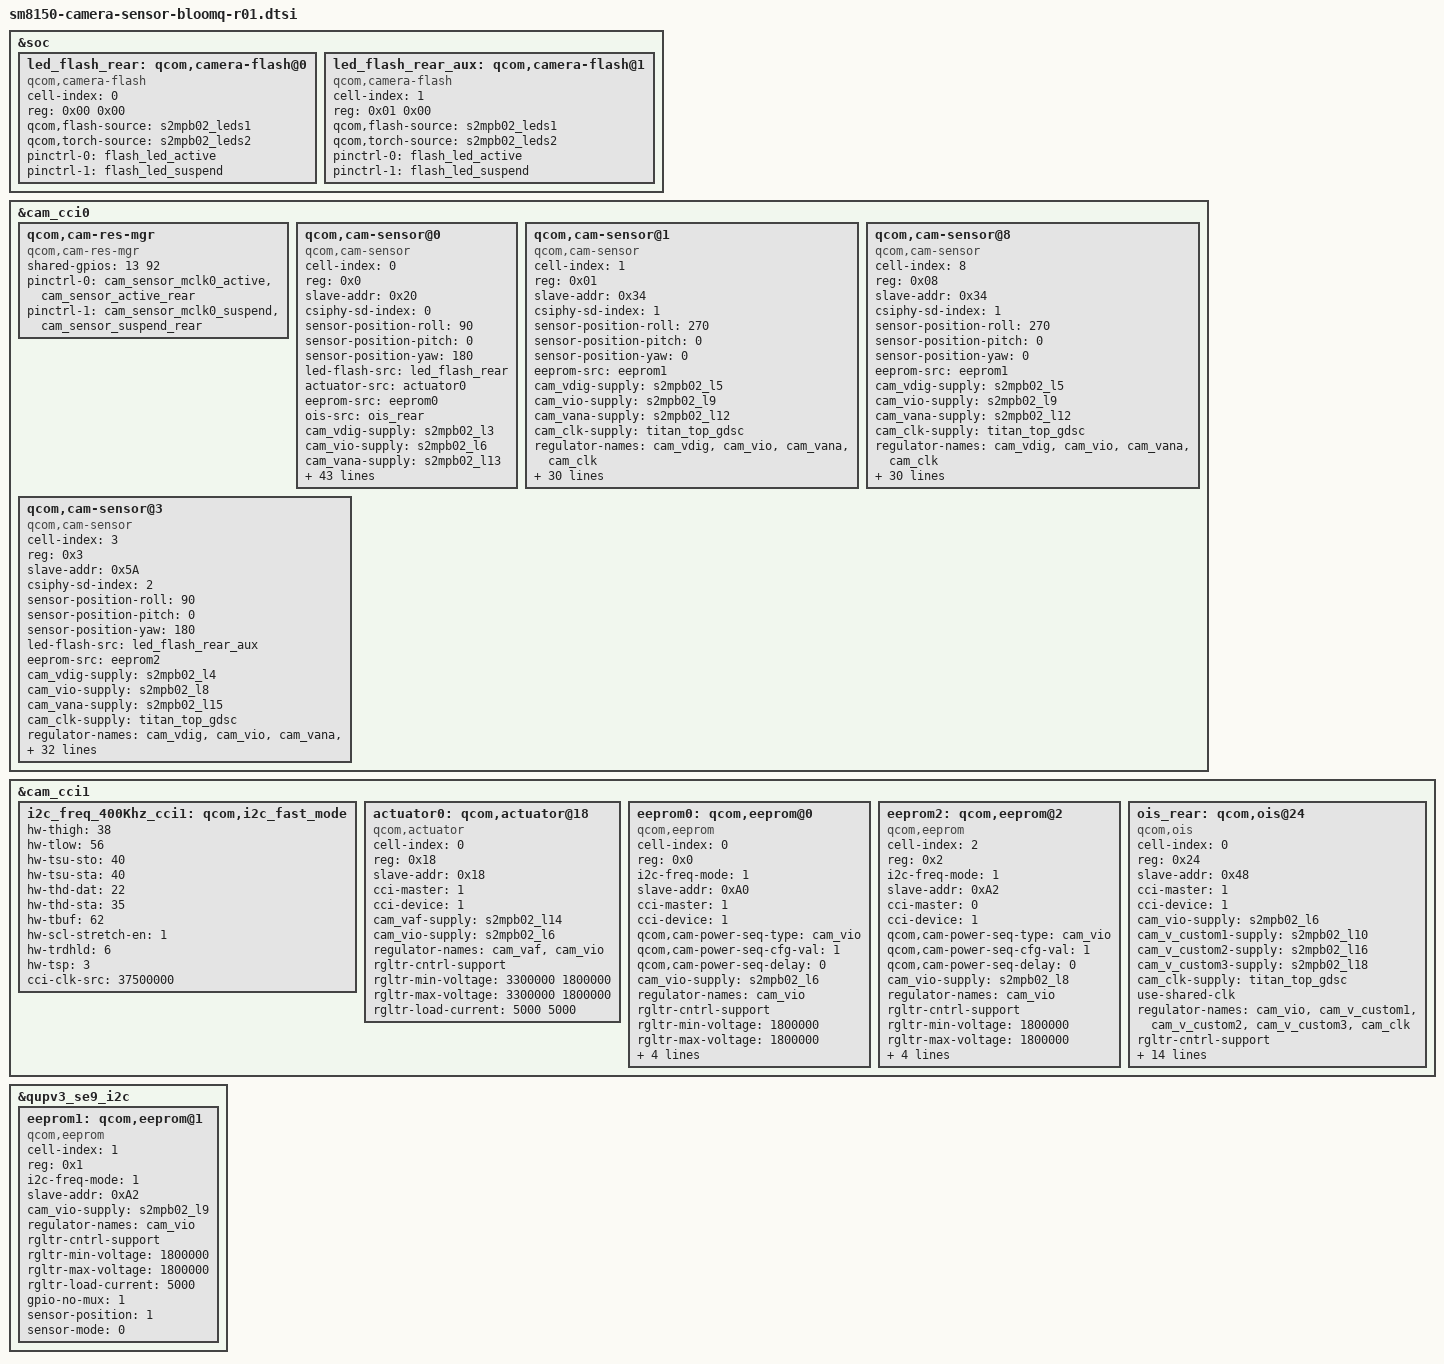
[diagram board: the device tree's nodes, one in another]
/*
 * Copyright (c) 2018, The Linux Foundation. All rights reserved.
 *
 * This program is free software; you can redistribute it and/or modify
 * it under the terms of the GNU General Public License version 2 and
 * only version 2 as published by the Free Software Foundation.
 *
 * This program is distributed in the hope that it will be useful,
 * but WITHOUT ANY WARRANTY; without even the implied warranty of
 * MERCHANTABILITY or FITNESS FOR A PARTICULAR PURPOSE.  See the
 * GNU General Public License for more details.
 */

&soc{
	led_flash_rear: qcom,camera-flash@0 {
		cell-index = <0>;
		reg = <0x00 0x00>;
		compatible = "qcom,camera-flash";
		qcom,flash-source = <&s2mpb02_leds1>;
		qcom,torch-source = <&s2mpb02_leds2>;
		pinctrl-names = "cam_default", "cam_suspend";
		pinctrl-0 = <&flash_led_active>;
		pinctrl-1 = <&flash_led_suspend>;
		status = "ok";
	};

	led_flash_rear_aux: qcom,camera-flash@1 {
		cell-index = <1>;
		reg = <0x01 0x00>;
		compatible = "qcom,camera-flash";
		qcom,flash-source = <&s2mpb02_leds1>;
		qcom,torch-source = <&s2mpb02_leds2>;
		pinctrl-names = "cam_default", "cam_suspend";
		pinctrl-0 = <&flash_led_active>;
		pinctrl-1 = <&flash_led_suspend>;
		status = "ok";
	};
};


&cam_cci0 {
	/*qcom,cam-res-mgr {
		compatible = "qcom,cam-res-mgr";
		shared-gpios = <13 15>;
		pinctrl-names = "cam_res_mgr_default", "cam_res_mgr_suspend";
		status = "ok";
		pinctrl-0 = <&cam_sensor_mclk0_active
		    &cam_sensor_mclk2_active>;
		pinctrl-1 = <&cam_sensor_mclk0_suspend
    		&cam_sensor_mclk2_suspend>;
	};*/
	qcom,cam-res-mgr {
		compatible = "qcom,cam-res-mgr";
		shared-gpios = <13 92>;
		pinctrl-names = "cam_res_mgr_default", "cam_res_mgr_suspend";
		status = "ok";
		pinctrl-0 = <&cam_sensor_mclk0_active &cam_sensor_active_rear>;
		pinctrl-1 = <&cam_sensor_mclk0_suspend &cam_sensor_suspend_rear>;
	};

	qcom,cam-sensor@0 {
                cell-index = <0>; /*REAR MAIN*/
                compatible = "qcom,cam-sensor";
                reg = <0x0>;
                slave-addr = <0x20>;
                csiphy-sd-index = <0>;
                sensor-position-roll = <90>;
                sensor-position-pitch = <0>;
                sensor-position-yaw = <180>;
                led-flash-src = <&led_flash_rear>;
                actuator-src = <&actuator0>;
                eeprom-src = <&eeprom0>;
                ois-src = <&ois_rear>;
                cam_vdig-supply = <&s2mpb02_l3>;        //VDD_MAINCAM_1P05
                cam_vio-supply = <&s2mpb02_l6>;         //VDD_MAINCAM_IO_1P8
                cam_vana-supply = <&s2mpb02_l13>;       //VDD_MAINCAM_A2P4
                cam_vaf-supply = <&s2mpb02_l14>;        //VDD_MAINCAM_AF_3P3
                cam_v_custom1-supply = <&s2mpb02_l2>;   //VDD_MAINCAM_RET_1P05
                cam_v_custom2-supply = <&s2mpb02_l1>;   //VDD_MAINCAM_DRAM_1P1
                cam_v_custom3-supply = <&s2mpb02_l10>;  //VDD_OIS_1P8
                cam_v_custom4-supply = <&s2mpb02_l16>;  //VDD_OIS_2P8
                cam_v_custom5-supply = <&s2mpb02_l18>;  //VDD_OIS_VM_2P8
                cam_v_custom6-supply = <&s2mpb02_l17>;  //VDD_MAINCAM_A2P8
                cam_clk-supply = <&titan_top_gdsc>;
                regulator-names = "cam_vdig", "cam_vio", "cam_vana", "cam_vaf", "cam_v_custom1", "cam_v_custom2", "cam_v_custom3", "cam_v_custom4", "cam_v_custom5", "cam_v_custom6", "cam_clk";
                rgltr-cntrl-support;
                rgltr-min-voltage = <1050000 1800000 2400000 3300000 700000  1100000 1800000 2800000 2800000 2800000 0>;
                rgltr-max-voltage = <1050000 1800000 2400000 3300000 1050000 1100000 1800000 2800000 2800000 2800000 0>;
                rgltr-load-current = <200000 200000 200000 200000 200000 200000 200000 200000 200000 200000 200000 0>;
                gpio-no-mux = <0>;
                use-shared-clk;
                gpios = <&tlmm 13 0>, /* MCLK */
                        <&tlmm 92 0>; /* RESET */
                gpio-reset = <1>;
                gpio-req-tbl-num = <0 1>;
                gpio-req-tbl-flags = <1 0>;
                gpio-req-tbl-label = "CAMIF_MCLK0","CAM_RESET0";
                sensor-mode = <0>;
                cci-master = <0>;
                cci-device = <0>;
                status = "ok";
                clocks = <&clock_camcc CAM_CC_MCLK0_CLK>;
                clock-names = "cam_clk";
                clock-cntl-level = "turbo";
                clock-rates = <19200000>;

                cam,isp = <0>;                  // 0 : INT , 1 : EXT , 2 : SOC
                cam,cal_memory = <2>;           // 0 : N , 1 : FROM , 2 : EEPROM , 3 : OTP
                cam,read_version = <1>;         // 0 : SYSFS , 1 : CAMON
                cam,core_voltage = <1>;         // 0 : N , 1 : Y
                cam,upgrade = <2>;              // 0 : N , 1 : SYSFS , 2 : CAMON
                cam,fw_write = <3>;             // 0 : N , 1 : OS , 2 : SD , 3 : ALL
                cam,fw_dump = <1>;              // 0 : N , 1 : Y
                cam,companion_chip = <0>;       // 0 : N , 1 : Y
                cam,ois = <1>;                  // 0 : N , 1 : Y
                cam,dual_open = <0>;            // 0 : N , 1 : Y
                cam,valid = <1>;                // 0 : N , 1 : Y
            };
	qcom,cam-sensor@1 {
		cell-index = <1>; /*VT 10M*/
		compatible = "qcom,cam-sensor";
		reg = <0x01>;
		slave-addr = <0x34>;
		csiphy-sd-index = <1>;
		sensor-position-roll = <270>;
		sensor-position-pitch = <0>;
		sensor-position-yaw = <0>;
		eeprom-src = <&eeprom1>;
		cam_vdig-supply = <&s2mpb02_l5>;
		cam_vio-supply = <&s2mpb02_l9>;
		cam_vana-supply = <&s2mpb02_l12>;
		cam_clk-supply = <&titan_top_gdsc>;
		//cam_v_custom1-supply = <&s2mpb02_b2>;
		regulator-names = "cam_vdig", "cam_vio", "cam_vana", "cam_clk";
		rgltr-cntrl-support;
		rgltr-min-voltage = <1050000 1800000 2800000 0>;
		rgltr-max-voltage = <1050000 1800000 2800000 0>;
		rgltr-load-current = <200000 200000 20000 0>;
		gpio-no-mux = <0>;
//		use-shared-clk;
		pinctrl-names = "cam_default", "cam_suspend";
		pinctrl-0 = <&cam_sensor_mclk2_active &cam_sensor_active_front>;
		pinctrl-1 = <&cam_sensor_mclk2_suspend &cam_sensor_suspend_front>;
		gpios = <&tlmm 15 0>,
			    <&tlmm 81 0>;
		gpio-reset = <1>;
		gpio-req-tbl-num = <0 1>;
		gpio-req-tbl-flags = <1 0>;
		gpio-req-tbl-label = "CAMIF_MCLK2","CAM_RESET2";
		sensor-mode = <0>;
		cci-master = <1>;
		status = "ok";
		clocks = <&clock_camcc CAM_CC_MCLK2_CLK>;
		clock-names = "cam_clk";
		clock-cntl-level = "turbo";
		clock-rates = <24000000>;

		cam,isp = <0>;                  // 0 : INT , 1 : EXT , 2 : SOC
		cam,cal_memory = <2>;           // 0 : N , 1 : FROM , 2 : EEPROM , 3 : OTP
		cam,read_version = <0>;         // 0 : SYSFS , 1 : CAMON
		cam,core_voltage = <0>;         // 0 : N , 1 : Y
		cam,upgrade = <0>;              // 0 : N , 1 : SYSFS , 2 : CAMON
		cam,fw_write = <0>;             // 0 : N , 1 : OS , 2 : SD , 3 : ALL
		cam,fw_dump = <0>;              // 0 : N , 1 : Y
		cam,companion_chip = <0>;       // 0 : N , 1 : Y
		cam,ois = <0>;                  // 0 : N , 1 : Y
		cam,dual_open = <0>;            // 0 : N , 1 : Y
		cam,valid = <1>;                // 0 : N , 1 : Y
	};
	qcom,cam-sensor@8 {
		cell-index = <8>; /*VT 10M FULL*/
		compatible = "qcom,cam-sensor";
		reg = <0x08>;
		slave-addr = <0x34>;
		csiphy-sd-index = <1>;
		sensor-position-roll = <270>;
		sensor-position-pitch = <0>;
		sensor-position-yaw = <0>;
		eeprom-src = <&eeprom1>;
		cam_vdig-supply = <&s2mpb02_l5>;
		cam_vio-supply = <&s2mpb02_l9>;
		cam_vana-supply = <&s2mpb02_l12>;
		cam_clk-supply = <&titan_top_gdsc>;
		//cam_v_custom1-supply = <&s2mpb02_b2>;
		regulator-names = "cam_vdig", "cam_vio", "cam_vana", "cam_clk";
		rgltr-cntrl-support;
		rgltr-min-voltage = <1050000 1800000 2800000 0>;
		rgltr-max-voltage = <1050000 1800000 2800000 0>;
		rgltr-load-current = <200000 200000 20000 0>;
		gpio-no-mux = <0>;
//		use-shared-clk;
		pinctrl-names = "cam_default", "cam_suspend";
		pinctrl-0 = <&cam_sensor_mclk2_active &cam_sensor_active_front>;
		pinctrl-1 = <&cam_sensor_mclk2_suspend &cam_sensor_suspend_front>;
		gpios = <&tlmm 15 0>,
			    <&tlmm 81 0>;
		gpio-reset = <1>;
		gpio-req-tbl-num = <0 1>;
		gpio-req-tbl-flags = <1 0>;
		gpio-req-tbl-label = "CAMIF_MCLK2","CAM_RESET2";
		sensor-mode = <0>;
		cci-master = <1>;
		status = "ok";
		clocks = <&clock_camcc CAM_CC_MCLK2_CLK>;
		clock-names = "cam_clk";
		clock-cntl-level = "turbo";
		clock-rates = <24000000>;

		cam,isp = <0>;                  // 0 : INT , 1 : EXT , 2 : SOC
		cam,cal_memory = <2>;           // 0 : N , 1 : FROM , 2 : EEPROM , 3 : OTP
		cam,read_version = <0>;         // 0 : SYSFS , 1 : CAMON
		cam,core_voltage = <0>;         // 0 : N , 1 : Y
		cam,upgrade = <0>;              // 0 : N , 1 : SYSFS , 2 : CAMON
		cam,fw_write = <0>;             // 0 : N , 1 : OS , 2 : SD , 3 : ALL
		cam,fw_dump = <0>;              // 0 : N , 1 : Y
		cam,companion_chip = <0>;       // 0 : N , 1 : Y
		cam,ois = <0>;                  // 0 : N , 1 : Y
		cam,dual_open = <0>;            // 0 : N , 1 : Y
		cam,valid = <1>;                // 0 : N , 1 : Y
	};   
	qcom,cam-sensor@3 {
		cell-index = <3>; /* REAR ULTRA WIDE */
     		compatible = "qcom,cam-sensor";
		reg = <0x3>;
		slave-addr = <0x5A>;
		csiphy-sd-index = <2>;
		sensor-position-roll = <90>;
		sensor-position-pitch = <0>;
		sensor-position-yaw = <180>;
		led-flash-src = <&led_flash_rear_aux>;
		eeprom-src = <&eeprom2>;
		cam_vdig-supply = <&s2mpb02_l4>;
		cam_vio-supply = <&s2mpb02_l8>;
		cam_vana-supply = <&s2mpb02_l15>;
		cam_clk-supply = <&titan_top_gdsc>;
		regulator-names = "cam_vdig", "cam_vio", "cam_vana", "cam_clk";
		rgltr-cntrl-support;
		rgltr-min-voltage = <1050000 1800000 2800000 0>;
		rgltr-max-voltage = <1050000 1800000 2800000 0>;
		rgltr-load-current = <200000 200000 200000 0>;
		gpio-no-mux = <0>;
		pinctrl-names = "cam_default", "cam_suspend";
		pinctrl-0 = <&cam_sensor_mclk1_active &cam_sensor_rear3sw_active>;
		pinctrl-1 = <&cam_sensor_mclk1_suspend &cam_sensor_rear3sw_suspend>;
		gpios = <&tlmm 14 0>, /* MCLK */
      			    <&tlmm 21 0>; /* RESET */
		gpio-reset = <1>;
		gpio-req-tbl-num = <0 1>;
		gpio-req-tbl-flags = <1 0>;
		gpio-req-tbl-label = "CAMIF_MCLK1", "CAM_RESET1";
		sensor-mode = <0>;
		cci-master = <0>;
		cci-device = <1>;
		status = "ok";
		clocks = <&clock_camcc CAM_CC_MCLK1_CLK>;
		clock-names = "cam_clk";
		clock-cntl-level = "turbo";
		clock-rates = <19200000>;

		cam,isp = <0>;                  // 0 : INT , 1 : EXT , 2 : SOC
		cam,cal_memory = <2>;           // 0 : N , 1 : FROM , 2 : EEPROM , 3 : OTP
		cam,read_version = <0>;         // 0 : SYSFS , 1 : CAMON
		cam,core_voltage = <0>;         // 0 : N , 1 : Y
		cam,upgrade = <0>;              // 0 : N , 1 : SYSFS , 2 : CAMON
		cam,fw_write = <0>;             // 0 : N , 1 : OS , 2 : SD , 3 : ALL
		cam,fw_dump = <0>;              // 0 : N , 1 : Y
		cam,companion_chip = <0>;       // 0 : N , 1 : Y
		cam,ois = <0>;                  // 0 : N , 1 : Y
		cam,dual_open = <0>;            // 0 : N , 1 : Y
		cam,valid = <1>;                // 0 : N , 1 : Y
	};		
};
&cam_cci1 {
	/* This node is added to enable the "I2C Clock Stretching" for OIS module */
	i2c_freq_400Khz_cci1: qcom,i2c_fast_mode {
		hw-thigh = <38>;
		hw-tlow = <56>;
		hw-tsu-sto = <40>;
		hw-tsu-sta = <40>;
		hw-thd-dat = <22>;
		hw-thd-sta = <35>;
		hw-tbuf = <62>;
		hw-scl-stretch-en = <1>;
		hw-trdhld = <6>;
		hw-tsp = <3>;
		cci-clk-src = <37500000>;
		status = "ok";
	};
	actuator0: qcom,actuator@18 { /* Wide */
		cell-index = <0>;
		reg = <0x18>;
		slave-addr = <0x18>;
		compatible = "qcom,actuator";
		cci-master = <1>;
		cci-device = <1>;
		cam_vaf-supply = <&s2mpb02_l14>;
		cam_vio-supply = <&s2mpb02_l6>;
		regulator-names = "cam_vaf", "cam_vio";
		rgltr-cntrl-support;
		rgltr-min-voltage = <3300000 1800000>;
		rgltr-max-voltage = <3300000 1800000>;
		rgltr-load-current = <5000 5000>;
		status = "ok";
	};

	eeprom0: qcom,eeprom@0 {
		cell-index = <0>;
		reg = <0x0>;
		compatible = "qcom,eeprom";
		i2c-freq-mode = <1>;
		slave-addr = <0xA0>;
		//eeprom-name= "cat24c512c8utr";

		cci-master = <1>;
		cci-device = <1>;

		qcom,cam-power-seq-type = "cam_vio";
		qcom,cam-power-seq-cfg-val = <1>;
		qcom,cam-power-seq-delay = <0>;

		cam_vio-supply = <&s2mpb02_l6>; /* VDD_MAINCAM_IO_1P8 */
		regulator-names = "cam_vio";
		rgltr-cntrl-support;
		rgltr-min-voltage = <1800000>;
		rgltr-max-voltage = <1800000>;
		rgltr-load-current = <5000>;
		gpio-no-mux = <1>;
		sensor-position = <0>;
		sensor-mode = <0>;
		status = "ok";
	};

	eeprom2: qcom,eeprom@2 { /* Ultra Wide */
		cell-index = <2>;
		reg = <0x2>;
		compatible = "qcom,eeprom";
		i2c-freq-mode = <1>;
		slave-addr = <0xA2>;
		//eeprom-name= "gt24p128ca2";

		cci-master = <0>;
		cci-device = <1>;

		qcom,cam-power-seq-type = "cam_vio";
		qcom,cam-power-seq-cfg-val = <1>;
		qcom,cam-power-seq-delay = <0>;

		cam_vio-supply = <&s2mpb02_l8>; /* VDD_MAINCAM_IO_1P8 */
		regulator-names = "cam_vio";
		rgltr-cntrl-support;
		rgltr-min-voltage = <1800000>;
		rgltr-max-voltage = <1800000>;
		rgltr-load-current = <5000>;
		gpio-no-mux = <1>;
		sensor-position = <0>;
		sensor-mode = <0>;
		status = "ok";
	};

	ois_rear: qcom,ois@24  {
		compatible = "qcom,ois";
		cell-index = <0>;
		reg = <0x24>;
		slave-addr = <0x48>;
		cci-master = <1>;
		cci-device = <1>;
		cam_vio-supply = <&s2mpb02_l6>;             //VDD_MAINCAM_IO_1P8
		cam_v_custom1-supply = <&s2mpb02_l10>;      // VDD_OIS_1P8
		cam_v_custom2-supply = <&s2mpb02_l16>;      // VDD_OIS_2P8
		cam_v_custom3-supply = <&s2mpb02_l18>;      // VDD_OIS_VM_2P8                 
		cam_clk-supply = <&titan_top_gdsc>;
		use-shared-clk;

		regulator-names = "cam_vio", "cam_v_custom1","cam_v_custom2","cam_v_custom3","cam_clk";
		rgltr-cntrl-support;
		rgltr-min-voltage = <1800000 1800000 2800000 2800000 0>;
		rgltr-max-voltage = <1800000 1800000 2800000 2800000 0>;
		rgltr-load-current = <5000 5000 5000 5000 0>;
		gpio-no-mux = <0>;

		gpios = <&tlmm 13 0>,
				 <&tlmm 92 0>;                 
		gpio-reset = <1>;
		gpio-req-tbl-num = <0 1>;
		gpio-req-tbl-flags = <1 0>;
		gpio-req-tbl-label = "CAMIF_MCLK0","CAM_RESET0";

		clocks = <&clock_camcc CAM_CC_MCLK0_CLK>;
		clock-names = "cam_clk";
		clock-cntl-level = "turbo";
		clock-rates = <24000000>;

		status = "ok";
	};
};

&qupv3_se9_i2c {
	status = "ok";

	eeprom1: qcom,eeprom@1 {
		cell-index = <1>;
		reg = <0x1>;
		compatible = "qcom,eeprom";
		i2c-freq-mode = <1>;
		slave-addr = <0xA2>;

		cam_vio-supply = <&s2mpb02_l9>;
		regulator-names = "cam_vio";
		rgltr-cntrl-support;
		rgltr-min-voltage = <1800000>;
		rgltr-max-voltage = <1800000>;
		rgltr-load-current = <5000>;
		gpio-no-mux = <1>;
		sensor-position = <1>;
		sensor-mode = <0>;
		status = "ok";
	};
};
